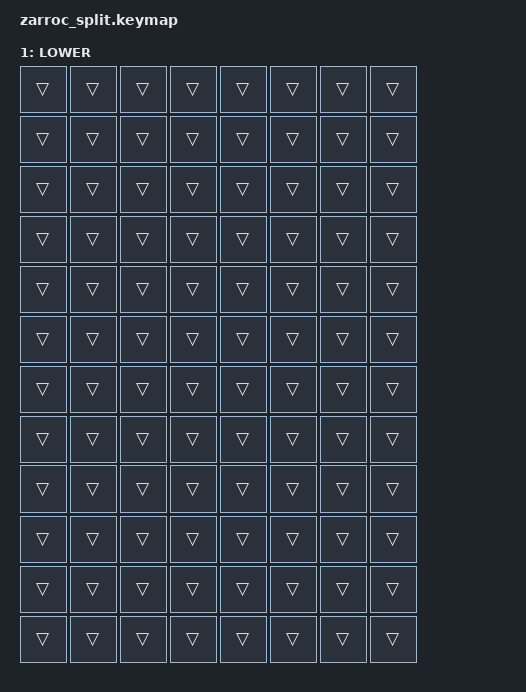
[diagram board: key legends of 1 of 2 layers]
/*
 * Zarroc Split —— 量产物大小用的最小键位表（两层，第二层全是 &trans）。
 * 真正做键盘时要按 matrix.md 的逐格对照重写。
 */
#include <behaviors.dtsi>
#include <dt-bindings/zmk/keys.h>

/ {
    keymap {
        compatible = "zmk,keymap";

        base {
            display-name = "BASE";
            bindings = <
                &kp ESC &kp F1 &kp F2 &kp F3 &kp F4 &kp F5 &kp F6 &kp MINUS
                &kp N1 &kp N2 &kp N3 &kp N4 &kp N5 &kp N6 &kp TAB &kp Q
                &kp W &kp E &kp R &kp T &kp Y &kp TAB &kp A &kp S
                &kp D &kp F &kp G &kp H &kp LSHFT &kp Z &kp X &kp C
                &kp V &kp B &kp N &kp LCTRL &kp LALT &kp SPACE &mo 1 &kp LGUI
                &none &none &kp BSPC &kp ENTER &kp SPACE &kp SPACE &kp F7 &kp F8
                &kp F9 &kp F10 &kp F11 &kp F12 &none &kp N6 &kp N7 &kp N8
                &kp N9 &kp N0 &kp EQUAL &none &kp T &kp Y &kp U &kp I
                &kp O &kp P &none &kp G &kp H &kp J &kp K &kp L
                &kp SEMI &none &kp B &kp N &kp M &kp COMMA &kp DOT &kp SLASH
                &none &none &kp BSPC &kp DEL &mo 1 &kp ENTER &none &none
                &kp SPACE &kp SPACE &kp ENTER &kp BSPC
            >;
        };

        lower {
            display-name = "LOWER";
            bindings = <
                &trans &trans &trans &trans &trans &trans &trans &trans
                &trans &trans &trans &trans &trans &trans &trans &trans
                &trans &trans &trans &trans &trans &trans &trans &trans
                &trans &trans &trans &trans &trans &trans &trans &trans
                &trans &trans &trans &trans &trans &trans &trans &trans
                &trans &trans &trans &trans &trans &trans &trans &trans
                &trans &trans &trans &trans &trans &trans &trans &trans
                &trans &trans &trans &trans &trans &trans &trans &trans
                &trans &trans &trans &trans &trans &trans &trans &trans
                &trans &trans &trans &trans &trans &trans &trans &trans
                &trans &trans &trans &trans &trans &trans &trans &trans
                &trans &trans &trans &trans &trans &trans &trans &trans
            >;
        };
    };
};
